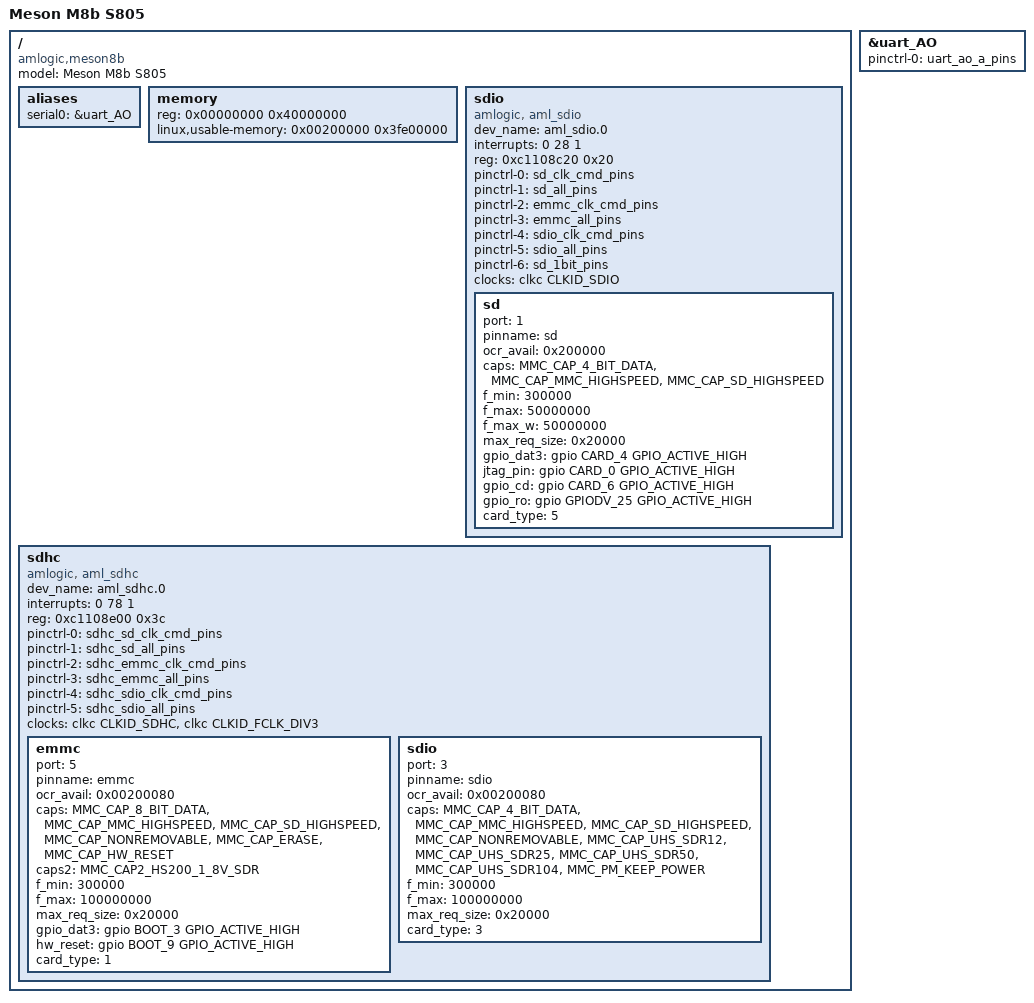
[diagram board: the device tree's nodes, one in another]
/*
 * arch/arm/boot/dts/amlogic/meson8b_m200.dts
 *
 * Copyright (C) 2017 Amlogic, Inc. All rights reserved.
 *
 * This program is free software; you can redistribute it and/or modify
 * it under the terms of the GNU General Public License as published by
 * the Free Software Foundation; either version 2 of the License, or
 * (at your option) any later version.
 *
 * This program is distributed in the hope that it will be useful, but WITHOUT
 * ANY WARRANTY; without even the implied warranty of MERCHANTABILITY or
 * FITNESS FOR A PARTICULAR PURPOSE.  See the GNU General Public License for
 * more details.
 *
 */

/dts-v1/;
#include "meson8b.dtsi"

/ {
	model = "Meson M8b S805";
	compatible = "amlogic,meson8b";

	aliases {
		serial0 = &uart_AO;
	};

	memory {
		reg = <0x00000000 0x40000000>;
		linux,usable-memory = <0x00200000 0x3fe00000>;
	};

	sdio {
		compatible = "amlogic, aml_sdio";
		dev_name = "aml_sdio.0";
		status = "okay";
		interrupts = <0 28 1>;
		reg = <0xc1108c20 0x20>;
		pinctrl-names = "sd_clk_cmd_pins",
			"sd_all_pins",
			"emmc_clk_cmd_pins",
			"emmc_all_pins",
			"sdio_clk_cmd_pins",
			"sdio_all_pins",
			"sd_1bit_pins";
		pinctrl-0 = <&sd_clk_cmd_pins>;
		pinctrl-1 = <&sd_all_pins>;
		pinctrl-2 = <&emmc_clk_cmd_pins>;
		pinctrl-3 = <&emmc_all_pins>;
		pinctrl-4 = <&sdio_clk_cmd_pins>;
		pinctrl-5 = <&sdio_all_pins>;
		pinctrl-6 = <&sd_1bit_pins>;
		clocks = <&clkc CLKID_SDIO>;
		clock-names = "core";

		sd {
			status = "okay";
			port = <1>;
			/* 0:sdio_a,
			 * 1:sdio_b,
			 * 2:sdio_c,
			 * 3:sdhc_a,
			 * 4:sdhc_b,
			 * 5:sdhc_c
			 */
			pinname = "sd";
			ocr_avail = <0x200000>; /**VDD voltage 3.3 ~ 3.4 */
			caps = "MMC_CAP_4_BIT_DATA",
				 "MMC_CAP_MMC_HIGHSPEED",
				 "MMC_CAP_SD_HIGHSPEED";
			f_min = <300000>;
			f_max = <50000000>;
			f_max_w = <50000000>;
			max_req_size = <0x20000>; /*128KB*/
			gpio_dat3 = <&gpio CARD_4 GPIO_ACTIVE_HIGH>;
			jtag_pin = <&gpio CARD_0 GPIO_ACTIVE_HIGH>;
			gpio_cd = <&gpio CARD_6 GPIO_ACTIVE_HIGH>;
			gpio_ro = <&gpio GPIODV_25 GPIO_ACTIVE_HIGH>;
			card_type = <5>;
			/* 0:unknown,
			 * 1:mmc card(include eMMC),
			 * 2:sd card(include tSD),
			 * 3:sdio device(ie:sdio-wifi),
			 * 4:SD combo (IO+mem) card,
			 * 5:NON sdio device(means sd/mmc card),
			 * other:reserved
			 */
		};
	};

	sdhc {
		compatible = "amlogic, aml_sdhc";
		dev_name = "aml_sdhc.0";
		status = "okay";
		interrupts = <0 78 1>;
		reg = <0xc1108e00 0x3c>;
		pinctrl-names = "sdhc_sd_clk_cmd_pins",
			"sdhc_sd_all_pins",
			"sdhc_emmc_clk_cmd_pins",
			"sdhc_emmc_all_pins",
			"sdhc_sdio_clk_cmd_pins",
			"sdhc_sdio_all_pins";
		pinctrl-0 = <&sdhc_sd_clk_cmd_pins>;
		pinctrl-1 = <&sdhc_sd_all_pins>;
		pinctrl-2 = <&sdhc_emmc_clk_cmd_pins>;
		pinctrl-3 = <&sdhc_emmc_all_pins>;
		pinctrl-4 = <&sdhc_sdio_clk_cmd_pins>;
		pinctrl-5 = <&sdhc_sdio_all_pins>;
		clocks = <&clkc CLKID_SDHC>,
			   <&clkc CLKID_FCLK_DIV3>;
		clock-names = "core", "div3";

		emmc {
			status = "okay";
			port = <5>;
			/* 0:sdio_a,
			 * 1:sdio_b,
			 * 2:sdio_c,
			 * 3:sdhc_a,
			 * 4:sdhc_b,
			 * 5:sdhc_c
			 */
			pinname = "emmc";
			ocr_avail = <0x00200080>;
			/* 3.3:0x200000, 1.8+3.3:0x00200080 */
			caps = "MMC_CAP_8_BIT_DATA",
				 "MMC_CAP_MMC_HIGHSPEED",
				 "MMC_CAP_SD_HIGHSPEED",
				 "MMC_CAP_NONREMOVABLE",
				 "MMC_CAP_ERASE",
				 "MMC_CAP_HW_RESET";
			caps2 = "MMC_CAP2_HS200_1_8V_SDR";
			f_min = <300000>;
			f_max = <100000000>;
			max_req_size = <0x20000>; /* 128KB */
			gpio_dat3 = <&gpio BOOT_3 GPIO_ACTIVE_HIGH>;
			hw_reset = <&gpio BOOT_9 GPIO_ACTIVE_HIGH>;
			card_type = <1>;
			/* 0:unknown,
			 * 1:mmc card(include eMMC),
			 * 2:sd card(include tSD),
			 * 3:sdio device(ie:sdio-wifi),
			 * 4:SD combo (IO+mem) card,
			 * 5:NON sdio device(means sd/mmc card),
			 * other:reserved
			 */
		};

		sdio {
			status = "okay";
			port = <3>;
			/* 0:sdio_a,
			 * 1:sdio_b,
			 * 2:sdio_c,
			 * 3:sdhc_a,
			 * 4:sdhc_b,
			 * 5:sdhc_c
			 */
			pinname = "sdio";
			ocr_avail = <0x00200080>;
			/* 3.3:0x200000, 1.8+3.3:0x00200080 */
			caps = "MMC_CAP_4_BIT_DATA",
				 "MMC_CAP_MMC_HIGHSPEED",
				 "MMC_CAP_SD_HIGHSPEED",
				 "MMC_CAP_NONREMOVABLE",
				 "MMC_CAP_UHS_SDR12",
				 "MMC_CAP_UHS_SDR25",
				 "MMC_CAP_UHS_SDR50",
				 "MMC_CAP_UHS_SDR104",
				 "MMC_PM_KEEP_POWER";
			f_min = <300000>;
			f_max = <100000000>;
			max_req_size = <0x20000>; /* 128KB */
			card_type = <3>;
			/* 0:unknown,
			 * 1:mmc card(include eMMC),
			 * 2:sd card(include tSD),
			 * 3:sdio device(ie:sdio-wifi),
			 * 4:SD combo (IO+mem) card,
			 * 5:NON sdio device(means sd/mmc card),
			 * other:reserved
			 */
		};
	};
};

&uart_AO {
	status = "okay";
	pinctrl-0 = <&uart_ao_a_pins>;
	pinctrl-names = "default";
};
